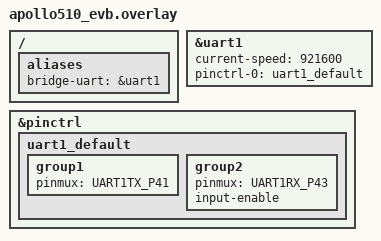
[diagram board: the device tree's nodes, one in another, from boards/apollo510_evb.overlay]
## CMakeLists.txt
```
# SPDX-License-Identifier: Apache-2.0
cmake_minimum_required(VERSION 3.20.0)
find_package(Zephyr REQUIRED HINTS $ENV{ZEPHYR_BASE})
project(robotics_control_loop)

target_sources(app PRIVATE
  src/main.c
  src/control.c
  src/plant.c
)

if(CONFIG_APP_TRANSPORT_SERIAL OR CONFIG_APP_TRANSPORT_UDP)
  target_sources(app PRIVATE src/bridge.c src/framing.c)
endif()
target_sources_ifdef(CONFIG_APP_TRANSPORT_SERIAL app PRIVATE src/bridge_serial.c)
target_sources_ifdef(CONFIG_APP_TRANSPORT_UDP app PRIVATE src/bridge_udp.c)
```

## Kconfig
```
# SPDX-License-Identifier: Apache-2.0
mainmenu "Robotics control loop sample"

choice APP_TRANSPORT
	prompt "Telemetry/command bridge"
	default APP_TRANSPORT_NONE
	help
	  Optional bridge that exports sensor/actuator telemetry and
	  accepts setpoint/e-stop commands over a byte transport. The
	  control loop itself has no transport knowledge either way.

config APP_TRANSPORT_NONE
	bool "None (local loop only)"

config APP_TRANSPORT_SERIAL
	bool "Serial (UART named by the bridge-uart alias)"
	depends on SERIAL && UART_INTERRUPT_DRIVEN

config APP_TRANSPORT_UDP
	bool "UDP socket"
	depends on NET_SOCKETS

endchoice

config APP_UDP_LOCAL_PORT
	int "UDP local port"
	depends on APP_TRANSPORT_UDP
	default 17448

config APP_UDP_PEER_ADDR
	string "UDP peer IPv4 address"
	depends on APP_TRANSPORT_UDP
	default "127.0.0.1"

config APP_UDP_PEER_PORT
	int "UDP peer port"
	depends on APP_TRANSPORT_UDP
	default 17448

source "Kconfig.zephyr"
```

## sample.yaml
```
sample:
  name: Robotics control loop
  description: Deterministic zbus control loop with acquisition timestamps
    and a pluggable transport bridge
common:
  tags:
    - robotics
    - zbus
  harness: console
  timeout: 60
  harness_config:
    type: multi_line
    ordered: false
    regex:
      - "loop: n="
      - "estop: actuator commanded to zero"
    record:
      regex:
        - "RECORD:(?P<metrics>.*)"
      as_json: ["metrics"]
  integration_platforms:
    - native_sim
tests:
  sample.robotics.control_loop:
    platform_allow:
      - native_sim
      - native_sim/native/64
      - apollo510_evb
      - qemu_cortex_m3
  sample.robotics.control_loop.serial:
    extra_args: EXTRA_CONF_FILE="overlay-serial.conf"
    platform_allow:
      - native_sim
      - native_sim/native/64
      - apollo510_evb
  sample.robotics.control_loop.udp:
    extra_args: EXTRA_CONF_FILE="overlay-udp.conf"
    platform_allow:
      - native_sim
      - native_sim/native/64
```

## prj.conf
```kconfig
CONFIG_ZBUS=y
CONFIG_FPU=y
```

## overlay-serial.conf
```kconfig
CONFIG_APP_TRANSPORT_SERIAL=y
CONFIG_SERIAL=y
CONFIG_UART_INTERRUPT_DRIVEN=y
```

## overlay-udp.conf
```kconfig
CONFIG_APP_TRANSPORT_UDP=y
# NSOS offloaded sockets: zero host-side setup on native_sim. Non-native
# boards need their own network configuration instead of this block.
CONFIG_NETWORKING=y
CONFIG_NET_DRIVERS=y
CONFIG_NET_SOCKETS=y
CONFIG_NET_SOCKETS_OFFLOAD=y
CONFIG_NET_NATIVE_OFFLOADED_SOCKETS=y
CONFIG_ETH_NATIVE_TAP=n
```

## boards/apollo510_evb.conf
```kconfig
# One kernel tick per stimer cycle: deadlines land on hardware timer
# edges and the wakeup-jitter numbers carry no tick-rounding bias.
CONFIG_SYS_CLOCK_TICKS_PER_SEC=32768
# The board defconfig enables PM; disable it so the measured jitter is
# scheduling, not wakeup-from-sleep.
CONFIG_PM=n
CONFIG_PM_DEVICE=n
CONFIG_PM_DEVICE_RUNTIME=n
```

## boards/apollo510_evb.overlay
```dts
/*
 * Bridge link on UART1 (TX P41, RX P43), mirroring the pin choice used
 * by the Ambiq robotics module samples on this EVB.
 *
 * Copyright (c) 2026 Ambiq Micro Inc. <www.ambiq.com>
 *
 * SPDX-License-Identifier: Apache-2.0
 */
/ {
	aliases {
		bridge-uart = &uart1;
	};
};

&uart1 {
	status = "okay";
	current-speed = <921600>;
	pinctrl-0 = <&uart1_default>;
	pinctrl-names = "default";
};

&pinctrl {
	uart1_default: uart1_default {
		group1 {
			pinmux = <UART1TX_P41>;
		};
		group2 {
			pinmux = <UART1RX_P43>;
			input-enable;
		};
	};
};
```

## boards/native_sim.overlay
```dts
/*
 * Copyright (c) 2026 Ambiq Micro Inc. <www.ambiq.com>
 *
 * SPDX-License-Identifier: Apache-2.0
 */
/ {
	aliases {
		bridge-uart = &uart1;
	};
};

&uart1 {
	status = "okay";
};
```

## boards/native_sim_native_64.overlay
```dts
/*
 * Copyright (c) 2026 Ambiq Micro Inc. <www.ambiq.com>
 *
 * SPDX-License-Identifier: Apache-2.0
 */
#include "native_sim.overlay"
```

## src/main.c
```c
/*
 * Robotics control-loop sample: deterministic 100 Hz closed loop over
 * zbus with acquisition timestamps and a pluggable transport bridge.
 * See README.rst for the control-period budget and how to read the
 * output.
 *
 * main() only orchestrates the demo: a square-wave setpoint, then an
 * emergency stop. The loop itself lives in control.c and never calls
 * into a transport - remote setpoints and telemetry go through the
 * bridge, which is just another zbus observer.
 *
 * Copyright (c) 2026 Ambiq Micro Inc. <www.ambiq.com>
 *
 * SPDX-License-Identifier: Apache-2.0
 */
#include <zephyr/sys/printk.h>

#include "app.h"

int main(void)
{
	uint32_t seq = 0;

	printk("robotics control_loop sample on %s (period %u us)\n",
	       CONFIG_BOARD,
	       (uint32_t)k_ticks_to_us_floor64(CONTROL_PERIOD_TICKS));

	control_start();

	/* square-wave setpoint until the demo's cycle budget is spent */
	while (loop_cycles < CONTROL_CYCLES) {
		struct setpoint_msg sp;

		sp.header.stamp_us = now_us();
		sp.header.seq = seq++;
		sp.header.type = WIRE_ID_SETPOINT;
		sp.header.source = 0;
		sp.velocity = ((seq / 2) % 2 == 0) ? 1.0f : -1.0f;
		(void)zbus_chan_pub(&setpoint_chan, &sp, K_MSEC(10));
		k_sleep(K_MSEC(500));
	}

	/* e-stop: the actuator latches to zero via its own listener */
	struct estop_msg stop;

	stop.header.stamp_us = now_us();
	stop.header.seq = 0;
	stop.header.type = WIRE_ID_ESTOP;
	stop.header.source = 0;
	stop.reason = 1;
	(void)zbus_chan_pub(&estop_chan, &stop, K_MSEC(10));
	k_sleep(K_MSEC(50));

	printk("estop: actuator commanded to zero, control loop halted\n");
	return 0;
}
```

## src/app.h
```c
/*
 * Copyright (c) 2026 Ambiq Micro Inc. <www.ambiq.com>
 *
 * SPDX-License-Identifier: Apache-2.0
 */
#ifndef SAMPLES_ROBOTICS_CONTROL_LOOP_APP_H
#define SAMPLES_ROBOTICS_CONTROL_LOOP_APP_H

#include <stdint.h>

#include <zephyr/kernel.h>
#include <zephyr/zbus/zbus.h>

/*
 * Plain-data message vocabulary. Every message starts with the same
 * header so generic tooling (and the wire bridge) can treat them
 * uniformly. stamp_us always carries *acquisition* time: derived messages
 * propagate the stamp of the sensor sample that caused them, which is
 * what makes end-to-end latency measurable at the actuation point.
 */
struct msg_header {
	uint64_t stamp_us; /* acquisition timestamp, microseconds */
	uint32_t seq;      /* per-producer sequence number        */
	uint16_t type;     /* wire id, see WIRE_ID_*              */
	uint16_t source;   /* producer id (0 = unspecified)       */
};

#define WIRE_ID_SETPOINT 1U
#define WIRE_ID_SENSOR   2U
#define WIRE_ID_ACTUATOR 3U
#define WIRE_ID_ESTOP    4U

struct setpoint_msg {
	struct msg_header header;
	float velocity; /* desired plant velocity */
};

struct sensor_msg {
	struct msg_header header;
	float velocity; /* measured plant velocity */
};

struct actuator_msg {
	struct msg_header header;
	float command; /* normalized actuator command, -1..1 */
};

struct estop_msg {
	struct msg_header header;
	uint8_t reason;
};

ZBUS_CHAN_DECLARE(setpoint_chan);
ZBUS_CHAN_DECLARE(sensor_chan);
ZBUS_CHAN_DECLARE(actuator_chan);
ZBUS_CHAN_DECLARE(estop_chan);

static inline uint64_t now_us(void)
{
	return k_ticks_to_us_floor64(k_uptime_ticks());
}

/* control loop parameters */
#define CONTROL_RATE_HZ     100U
#define CONTROL_PERIOD_TICKS                                                   \
	MAX(1, CONFIG_SYS_CLOCK_TICKS_PER_SEC / CONTROL_RATE_HZ)
#define CONTROL_CYCLES      300U /* run length before the e-stop demo */

/* plant simulation (plant.c) */
void plant_apply(float command);
float plant_step(float dt_s);

/* control.c */
void control_start(void);
extern volatile uint32_t loop_cycles;

/* wire bridge (bridge.c, compiled unless APP_TRANSPORT_NONE) */
#if defined(CONFIG_APP_TRANSPORT_SERIAL) || defined(CONFIG_APP_TRANSPORT_UDP)
void bridge_rx(const uint8_t *buf, size_t len);
struct bridge_backend {
	int (*init)(void);
	int (*write)(const uint8_t *buf, size_t len);
};
extern const struct bridge_backend bridge_backend;
#endif

#endif /* SAMPLES_ROBOTICS_CONTROL_LOOP_APP_H */
```

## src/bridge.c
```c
/*
 * Transport bridge: the loop's only connection to the outside world, and
 * itself just another zbus observer. Outbound, sensor and actuator
 * publications are framed and handed to the backend; inbound, decoded
 * setpoint and e-stop frames are published locally, so remote and local
 * producers are indistinguishable to the loop.
 *
 * The backend below this file is two functions (init + write, plus
 * calling bridge_rx() with received bytes) - the seam a TSN, Zenoh or
 * any other transport implementation drops into.
 *
 * Copyright (c) 2026 Ambiq Micro Inc. <www.ambiq.com>
 *
 * SPDX-License-Identifier: Apache-2.0
 */
#include <zephyr/sys/printk.h>

#include "app.h"
#include "framing.h"

static struct frame_decoder decoder;
static K_MUTEX_DEFINE(tx_lock);

/* the thread republishing an inbound frame must not re-export it */
static k_tid_t rx_pub_tid;

static void bridge_tx(uint16_t id, const void *msg, size_t len)
{
	uint8_t buf[FRAME_MAX_PAYLOAD + FRAME_OVERHEAD];

	k_mutex_lock(&tx_lock, K_FOREVER);

	size_t n = frame_encode(id, msg, len, buf, sizeof(buf));

	if (n > 0) {
		(void)bridge_backend.write(buf, n);
	}
	k_mutex_unlock(&tx_lock);
}

static void export_cb(const struct zbus_channel *chan)
{
	if (k_current_get() == rx_pub_tid) {
		return;
	}
	if (chan == &sensor_chan) {
		bridge_tx(WIRE_ID_SENSOR, zbus_chan_const_msg(chan),
			  sizeof(struct sensor_msg));
	} else if (chan == &actuator_chan) {
		bridge_tx(WIRE_ID_ACTUATOR, zbus_chan_const_msg(chan),
			  sizeof(struct actuator_msg));
	}
}
ZBUS_LISTENER_DEFINE(bridge_listener, export_cb);
ZBUS_CHAN_ADD_OBS(sensor_chan, bridge_listener, 5);
ZBUS_CHAN_ADD_OBS(actuator_chan, bridge_listener, 5);

static void frame_rx_cb(uint16_t id, const void *payload, size_t len,
			void *user)
{
	ARG_UNUSED(user);
	const struct zbus_channel *chan = NULL;

	if (id == WIRE_ID_SETPOINT && len == sizeof(struct setpoint_msg)) {
		chan = &setpoint_chan;
	} else if (id == WIRE_ID_ESTOP && len == sizeof(struct estop_msg)) {
		chan = &estop_chan;
	}
	if (chan == NULL) {
		return;
	}
	rx_pub_tid = k_current_get();
	(void)zbus_chan_pub(chan, payload, K_MSEC(5));
	rx_pub_tid = NULL;
}

void bridge_rx(const uint8_t *buf, size_t len)
{
	frame_decoder_feed(&decoder, buf, len);
}

static int bridge_init(void)
{
	frame_decoder_init(&decoder, frame_rx_cb, NULL);

	int rc = bridge_backend.init();

	if (rc != 0) {
		printk("bridge: backend init failed (%d)\n", rc);
	}
	return rc;
}
SYS_INIT(bridge_init, APPLICATION, CONFIG_APPLICATION_INIT_PRIORITY);
```

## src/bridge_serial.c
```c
/*
 * Serial bridge backend: interrupt-driven RX into a ring buffer decoded
 * on the system workqueue; polled TX. The UART comes from the
 * "bridge-uart" devicetree alias.
 *
 * Copyright (c) 2026 Ambiq Micro Inc. <www.ambiq.com>
 *
 * SPDX-License-Identifier: Apache-2.0
 */
#include <zephyr/device.h>
#include <zephyr/devicetree.h>
#include <zephyr/drivers/uart.h>
#include <zephyr/sys/ring_buffer.h>

#include "app.h"

static const struct device *const uart_dev =
	DEVICE_DT_GET(DT_ALIAS(bridge_uart));

RING_BUF_DECLARE(rx_ring, 512);
static struct k_work rx_work;

static int serial_write(const uint8_t *buf, size_t len)
{
	for (size_t i = 0; i < len; i++) {
		uart_poll_out(uart_dev, buf[i]);
	}
	return 0;
}

static void rx_work_fn(struct k_work *work)
{
	ARG_UNUSED(work);
	uint8_t buf[64];
	uint32_t n;

	while ((n = ring_buf_get(&rx_ring, buf, sizeof(buf))) > 0) {
		bridge_rx(buf, n);
	}
}

static void uart_isr(const struct device *dev, void *user_data)
{
	ARG_UNUSED(user_data);
	uint8_t buf[32];

	uart_irq_update(dev);
	while (uart_irq_rx_ready(dev) > 0) {
		int n = uart_fifo_read(dev, buf, sizeof(buf));

		if (n <= 0) {
			break;
		}
		(void)ring_buf_put(&rx_ring, buf, n);
	}
	k_work_submit(&rx_work);
}

static int serial_init(void)
{
	if (!device_is_ready(uart_dev)) {
		return -ENODEV;
	}
	k_work_init(&rx_work, rx_work_fn);
	uart_irq_callback_user_data_set(uart_dev, uart_isr, NULL);
	uart_irq_rx_enable(uart_dev);
	return 0;
}

const struct bridge_backend bridge_backend = {
	.init = serial_init,
	.write = serial_write,
};
```

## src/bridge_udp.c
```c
/*
 * UDP bridge backend: whole frames inside datagrams. On native_sim,
 * combine with NSOS offloaded sockets (overlay-udp.conf) for zero host
 * setup.
 *
 * Copyright (c) 2026 Ambiq Micro Inc. <www.ambiq.com>
 *
 * SPDX-License-Identifier: Apache-2.0
 */
#include <zephyr/net/socket.h>

#include "app.h"

static int sock = -1;
static struct sockaddr_in peer;

/*
 * Auto-started and gated on a semaphore: static threads are set up after
 * APPLICATION-level SYS_INIT, so starting the thread from init would be
 * silently undone.
 */
static K_SEM_DEFINE(udp_ready, 0, 1);

static void rx_thread(void *a, void *b, void *c)
{
	ARG_UNUSED(a); ARG_UNUSED(b); ARG_UNUSED(c);
	static uint8_t buf[256];

	k_sem_take(&udp_ready, K_FOREVER);

	while (1) {
		ssize_t n = zsock_recvfrom(sock, buf, sizeof(buf), 0, NULL,
					   NULL);

		if (n <= 0) {
			k_sleep(K_MSEC(10));
			continue;
		}
		bridge_rx(buf, (size_t)n);
	}
}
K_THREAD_DEFINE(bridge_udp_rx, 2048, rx_thread, NULL, NULL, NULL, 7, 0, 0);

static int udp_write(const uint8_t *buf, size_t len)
{
	if (sock < 0) {
		return -ENOTCONN;
	}
	ssize_t n = zsock_sendto(sock, buf, len, 0, (struct sockaddr *)&peer,
				 sizeof(peer));

	return (n == (ssize_t)len) ? 0 : -EIO;
}

static int udp_init(void)
{
	struct sockaddr_in local = {
		.sin_family = AF_INET,
		.sin_port = htons(CONFIG_APP_UDP_LOCAL_PORT),
		.sin_addr = { .s_addr = htonl(INADDR_ANY) },
	};

	sock = zsock_socket(AF_INET, SOCK_DGRAM, IPPROTO_UDP);
	if (sock < 0) {
		return -errno;
	}
	if (zsock_bind(sock, (struct sockaddr *)&local, sizeof(local)) < 0) {
		return -errno;
	}

	peer.sin_family = AF_INET;
	peer.sin_port = htons(CONFIG_APP_UDP_PEER_PORT);
	if (zsock_inet_pton(AF_INET, CONFIG_APP_UDP_PEER_ADDR,
			    &peer.sin_addr) != 1) {
		return -EINVAL;
	}

	k_sem_give(&udp_ready);
	return 0;
}

const struct bridge_backend bridge_backend = {
	.init = udp_init,
	.write = udp_write,
};
```

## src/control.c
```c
/*
 * The three stages of the loop, decoupled by zbus channels:
 *
 *   sensor thread (100 Hz, absolute deadlines) -> sensor_chan
 *   controller (subscriber thread, PI)         -> actuator_chan
 *   actuator (listener)                        -> plant / hardware
 *
 * The sensor thread sleeps to absolute deadlines (K_TIMEOUT_ABS_TICKS),
 * so the period cannot drift with execution time, and measures its own
 * wakeup jitter against each deadline. The actuator listener measures
 * end-to-end latency: sensor acquisition stamp -> actuation, possible
 * because derived messages propagate the causing sample's stamp.
 *
 * An e-stop latches the actuator to zero: safety does not depend on the
 * controller thread being alive.
 *
 * Copyright (c) 2026 Ambiq Micro Inc. <www.ambiq.com>
 *
 * SPDX-License-Identifier: Apache-2.0
 */
#include <zephyr/sys/printk.h>

#include "app.h"

ZBUS_CHAN_DEFINE(setpoint_chan, struct setpoint_msg, NULL, NULL,
		 ZBUS_OBSERVERS_EMPTY, ZBUS_MSG_INIT(0));
ZBUS_CHAN_DEFINE(sensor_chan, struct sensor_msg, NULL, NULL,
		 ZBUS_OBSERVERS(controller_sub), ZBUS_MSG_INIT(0));
ZBUS_CHAN_DEFINE(actuator_chan, struct actuator_msg, NULL, NULL,
		 ZBUS_OBSERVERS(actuator_listener), ZBUS_MSG_INIT(0));
ZBUS_CHAN_DEFINE(estop_chan, struct estop_msg, NULL, NULL,
		 ZBUS_OBSERVERS(estop_listener), ZBUS_MSG_INIT(0));

volatile uint32_t loop_cycles;

/* per-100-cycle stats windows, integer microseconds */
static uint32_t wake_min = UINT32_MAX, wake_max, wake_sum;
static volatile uint32_t e2e_min = UINT32_MAX, e2e_max, e2e_sum, e2e_n;
static volatile bool stopped;

/* ---- actuator (runs in the publisher's context) -------------------------- */

static void actuator_cb(const struct zbus_channel *chan)
{
	const struct actuator_msg *m = zbus_chan_const_msg(chan);

	if (stopped) {
		plant_apply(0.0f);
		return;
	}
	plant_apply(m->command);

	/* end-to-end: sensor acquisition -> actuation applied */
	uint32_t e2e = (uint32_t)(now_us() - m->header.stamp_us);

	e2e_min = MIN(e2e_min, e2e);
	e2e_max = MAX(e2e_max, e2e);
	e2e_sum += e2e;
	e2e_n++;
}
ZBUS_LISTENER_DEFINE(actuator_listener, actuator_cb);

static void estop_cb(const struct zbus_channel *chan)
{
	ARG_UNUSED(chan);
	stopped = true;
	plant_apply(0.0f);
}
ZBUS_LISTENER_DEFINE(estop_listener, estop_cb);

/* ---- controller: PI against the latest setpoint -------------------------- */

ZBUS_SUBSCRIBER_DEFINE(controller_sub, 4);

#define KP 0.8f
#define KI 2.5f

static void controller_thread(void *a, void *b, void *c)
{
	ARG_UNUSED(a); ARG_UNUSED(b); ARG_UNUSED(c);
	const struct zbus_channel *chan;
	float integ = 0.0f;
	uint32_t seq = 0;

	while (zbus_sub_wait(&controller_sub, &chan, K_FOREVER) == 0) {
		struct sensor_msg s;
		struct setpoint_msg sp;
		struct actuator_msg out;

		if (chan != &sensor_chan || stopped) {
			continue;
		}
		if (zbus_chan_read(&sensor_chan, &s, K_MSEC(2)) != 0 ||
		    zbus_chan_read(&setpoint_chan, &sp, K_MSEC(2)) != 0) {
			continue;
		}

		float err = sp.velocity - s.velocity;
		float dt = 1.0f / CONTROL_RATE_HZ;

		integ += err * dt;
		integ = CLAMP(integ, -0.5f, 0.5f);

		float u = CLAMP(KP * err + KI * integ, -1.0f, 1.0f);

		/* propagate the causing sample's acquisition stamp */
		out.header.stamp_us = s.header.stamp_us;
		out.header.seq = seq++;
		out.header.type = WIRE_ID_ACTUATOR;
		out.header.source = 0;
		out.command = u;
		(void)zbus_chan_pub(&actuator_chan, &out, K_MSEC(2));
	}
}
K_THREAD_DEFINE(controller_tid, 2048, controller_thread, NULL, NULL, NULL, 5,
		0, 0);

/* ---- sensor: 100 Hz on absolute deadlines -------------------------------- */

static void sensor_thread(void *a, void *b, void *c)
{
	ARG_UNUSED(a); ARG_UNUSED(b); ARG_UNUSED(c);
	uint32_t seq = 0;
	uint64_t hw_freq = (uint64_t)sys_clock_hw_cycles_per_sec();

	/* align to a tick, then run on absolute deadlines */
	k_sleep(K_TICKS(1));
	int64_t next = k_uptime_ticks();

	while (1) {
		next += CONTROL_PERIOD_TICKS;
		k_sleep(K_TIMEOUT_ABS_TICKS(next));

		/*
		 * Wakeup jitter vs the deadline, measured in the kernel
		 * timer's own clock domain (same clock as the deadline, so
		 * no cross-oscillator drift; resolution = 1 hw cycle).
		 */
		uint64_t deadline_cyc =
			((uint64_t)next * hw_freq) /
			CONFIG_SYS_CLOCK_TICKS_PER_SEC;
		uint64_t now_cyc = IS_ENABLED(
					   CONFIG_TIMER_HAS_64BIT_CYCLE_COUNTER)
					   ? k_cycle_get_64()
					   : (uint64_t)k_cycle_get_32();
		uint32_t wake_us =
			(now_cyc > deadline_cyc)
				? (uint32_t)k_cyc_to_us_floor64(now_cyc -
								deadline_cyc)
				: 0;

		struct sensor_msg s;

		s.header.stamp_us = now_us(); /* acquisition instant */
		s.header.seq = seq++;
		s.header.type = WIRE_ID_SENSOR;
		s.header.source = 0;
		s.velocity = plant_step(1.0f / CONTROL_RATE_HZ);
		(void)zbus_chan_pub(&sensor_chan, &s, K_MSEC(2));

		if (stopped) {
			continue; /* keep sampling; stats are done */
		}

		wake_min = MIN(wake_min, wake_us);
		wake_max = MAX(wake_max, wake_us);
		wake_sum += wake_us;
		loop_cycles++;

		if ((loop_cycles % 100) == 0) {
			printk("loop: n=%u period_us=%u wake_jitter_us min=%u avg=%u max=%u e2e_us min=%u avg=%u max=%u\n",
			       loop_cycles,
			       (uint32_t)k_ticks_to_us_floor64(
				       CONTROL_PERIOD_TICKS),
			       wake_min, wake_sum / 100, wake_max,
			       e2e_min, e2e_n ? e2e_sum / e2e_n : 0, e2e_max);
			if (loop_cycles == CONTROL_CYCLES) {
				printk("RECORD: {\"sample\":\"control_loop\",\"board\":\"%s\",\"n\":%u,\"wake_avg_us\":%u,\"wake_max_us\":%u,\"e2e_avg_us\":%u,\"e2e_max_us\":%u}\n",
				       CONFIG_BOARD, loop_cycles,
				       wake_sum / 100, wake_max,
				       e2e_n ? e2e_sum / e2e_n : 0, e2e_max);
			}
			wake_min = UINT32_MAX;
			wake_max = 0;
			wake_sum = 0;
			e2e_min = UINT32_MAX;
			e2e_max = 0;
			e2e_sum = 0;
			e2e_n = 0;
		}
	}
}
K_THREAD_DEFINE(sensor_tid, 2048, sensor_thread, NULL, NULL, NULL, 4, 0, 100);

void control_start(void)
{
	/* threads are statically defined; nothing to do (hook for ports) */
}
```

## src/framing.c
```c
/*
 * Byte framing for the transport bridge:
 *
 *   0x7E | id(u16 LE) | len(u16 LE) | payload[len] | crc16(u16 LE)
 *
 * CRC-16/CCITT-FALSE (poly 0x1021, init 0xFFFF) over id+len+payload.
 * Deliberately interoperable with vendor implementations of the same
 * framing; the decoder is a plain byte-stream state machine, so any
 * transport that delivers the bytes in order can carry it.
 *
 * Copyright (c) 2026 Ambiq Micro Inc. <www.ambiq.com>
 *
 * SPDX-License-Identifier: Apache-2.0
 */
#include <string.h>

#include "framing.h"

static uint16_t crc16_step(uint16_t crc, uint8_t byte)
{
	crc ^= (uint16_t)byte << 8;
	for (int i = 0; i < 8; i++) {
		crc = (crc & 0x8000U) ? (crc << 1) ^ 0x1021U : (crc << 1);
	}
	return crc;
}

static uint16_t crc16_buf(uint16_t crc, const uint8_t *buf, size_t len)
{
	for (size_t i = 0; i < len; i++) {
		crc = crc16_step(crc, buf[i]);
	}
	return crc;
}

size_t frame_encode(uint16_t id, const void *payload, size_t len,
		    uint8_t *out, size_t out_size)
{
	if (len > FRAME_MAX_PAYLOAD || out_size < len + FRAME_OVERHEAD) {
		return 0;
	}

	uint8_t hdr[4] = { (uint8_t)(id & 0xFF), (uint8_t)(id >> 8),
			   (uint8_t)(len & 0xFF), (uint8_t)(len >> 8) };
	uint16_t crc = 0xFFFF;

	crc = crc16_buf(crc, hdr, sizeof(hdr));
	crc = crc16_buf(crc, payload, len);

	out[0] = FRAME_SYNC;
	memcpy(&out[1], hdr, sizeof(hdr));
	memcpy(&out[5], payload, len);
	out[5 + len] = (uint8_t)(crc & 0xFF);
	out[6 + len] = (uint8_t)(crc >> 8);
	return len + FRAME_OVERHEAD;
}

void frame_decoder_init(struct frame_decoder *d, frame_cb_t cb, void *user)
{
	memset(d, 0, sizeof(*d));
	d->cb = cb;
	d->user = user;
}

void frame_decoder_feed(struct frame_decoder *d, const uint8_t *buf,
			size_t len)
{
	for (size_t i = 0; i < len; i++) {
		uint8_t b = buf[i];

		switch (d->state) {
		case FRAME_ST_SYNC:
			if (b == FRAME_SYNC) {
				d->state = FRAME_ST_ID_LO;
				d->crc = 0xFFFF;
			}
			break;
		case FRAME_ST_ID_LO:
			d->id = b;
			d->crc = crc16_step(d->crc, b);
			d->state = FRAME_ST_ID_HI;
			break;
		case FRAME_ST_ID_HI:
			d->id |= (uint16_t)b << 8;
			d->crc = crc16_step(d->crc, b);
			d->state = FRAME_ST_LEN_LO;
			break;
		case FRAME_ST_LEN_LO:
			d->len = b;
			d->crc = crc16_step(d->crc, b);
			d->state = FRAME_ST_LEN_HI;
			break;
		case FRAME_ST_LEN_HI:
			d->len |= (uint16_t)b << 8;
			d->crc = crc16_step(d->crc, b);
			if (d->len > FRAME_MAX_PAYLOAD) {
				d->state = FRAME_ST_SYNC; /* resync */
				break;
			}
			d->pos = 0;
			d->state = (d->len > 0) ? FRAME_ST_PAYLOAD
						: FRAME_ST_CRC_LO;
			break;
		case FRAME_ST_PAYLOAD:
			d->payload[d->pos++] = b;
			d->crc = crc16_step(d->crc, b);
			if (d->pos == d->len) {
				d->state = FRAME_ST_CRC_LO;
			}
			break;
		case FRAME_ST_CRC_LO:
			d->crc_rx = b;
			d->state = FRAME_ST_CRC_HI;
			break;
		case FRAME_ST_CRC_HI:
			d->crc_rx |= (uint16_t)b << 8;
			if (d->crc_rx == d->crc && d->cb != NULL) {
				d->cb(d->id, d->payload, d->len, d->user);
			}
			d->state = FRAME_ST_SYNC;
			break;
		default:
			d->state = FRAME_ST_SYNC;
			break;
		}
	}
}
```

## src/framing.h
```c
/*
 * Copyright (c) 2026 Ambiq Micro Inc. <www.ambiq.com>
 *
 * SPDX-License-Identifier: Apache-2.0
 */
#ifndef SAMPLES_ROBOTICS_CONTROL_LOOP_FRAMING_H
#define SAMPLES_ROBOTICS_CONTROL_LOOP_FRAMING_H

#include <stddef.h>
#include <stdint.h>

#define FRAME_SYNC        0x7EU
#define FRAME_MAX_PAYLOAD 64U
#define FRAME_OVERHEAD    7U /* sync + id(2) + len(2) + crc(2) */

typedef void (*frame_cb_t)(uint16_t id, const void *payload, size_t len,
			   void *user);

enum frame_state {
	FRAME_ST_SYNC,
	FRAME_ST_ID_LO,
	FRAME_ST_ID_HI,
	FRAME_ST_LEN_LO,
	FRAME_ST_LEN_HI,
	FRAME_ST_PAYLOAD,
	FRAME_ST_CRC_LO,
	FRAME_ST_CRC_HI,
};

struct frame_decoder {
	enum frame_state state;
	uint16_t id;
	uint16_t len;
	uint16_t pos;
	uint16_t crc;
	uint16_t crc_rx;
	uint8_t payload[FRAME_MAX_PAYLOAD];
	frame_cb_t cb;
	void *user;
};

size_t frame_encode(uint16_t id, const void *payload, size_t len,
		    uint8_t *out, size_t out_size);
void frame_decoder_init(struct frame_decoder *d, frame_cb_t cb, void *user);
void frame_decoder_feed(struct frame_decoder *d, const uint8_t *buf,
			size_t len);

#endif /* SAMPLES_ROBOTICS_CONTROL_LOOP_FRAMING_H */
```

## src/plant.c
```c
/*
 * Simulated plant: a first-order DC-motor-like system,
 *
 *   dv/dt = (K * u - v) / tau
 *
 * so the sample closes a real loop on every board, hardware or not. On a
 * real robot this file is replaced by the motor driver and encoder
 * feedback; nothing else in the sample changes.
 *
 * Copyright (c) 2026 Ambiq Micro Inc. <www.ambiq.com>
 *
 * SPDX-License-Identifier: Apache-2.0
 */
#include "app.h"

#define PLANT_GAIN 2.0f  /* steady-state velocity per unit command */
#define PLANT_TAU  0.15f /* time constant, seconds                 */

static float velocity;
static volatile float command;

void plant_apply(float cmd)
{
	command = cmd;
}

float plant_step(float dt_s)
{
	velocity += ((PLANT_GAIN * command) - velocity) * (dt_s / PLANT_TAU);
	return velocity;
}
```
